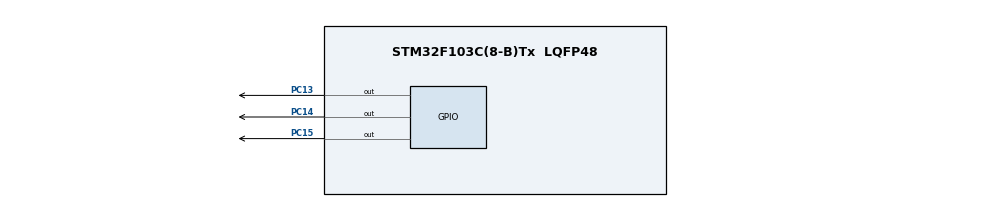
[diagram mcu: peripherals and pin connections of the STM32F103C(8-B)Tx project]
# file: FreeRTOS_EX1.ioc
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Mcu.Family=STM32F1
Mcu.Name=STM32F103C(8-B)Tx
Mcu.Package=LQFP48
NVIC.PriorityGroup=NVIC_PRIORITYGROUP_4
NVIC.TIM1_UP_IRQn=true\:15\:0\:true\:false\:true\:false\:true\:true
NVIC.TimeBase=TIM1_UP_IRQn
NVIC.TimeBaseIP=TIM1
PA13.Mode=Serial_Wire
PA13.Signal=SYS_JTMS-SWDIO
PA14.Mode=Serial_Wire
PA14.Signal=SYS_JTCK-SWCLK
PC13-TAMPER-RTC.Signal=GPIO_Output
PC14-OSC32_IN.Signal=GPIO_Output
PC15-OSC32_OUT.Signal=GPIO_Output
PD0-OSC_IN.Mode=HSE-External-Clock-Source
PD0-OSC_IN.Signal=RCC_OSC_IN
PD1-OSC_OUT.Mode=HSE-External-Clock-Source
PD1-OSC_OUT.Signal=RCC_OSC_OUT
ProjectManager.HeapSize=0x200
ProjectManager.StackSize=0x400
ProjectManager.TargetToolchain=STM32CubeIDE
RCC.APB1Freq_Value=8000000
RCC.APB2Freq_Value=8000000
VP_SYS_VS_tim1.Mode=TIM1
board=custom

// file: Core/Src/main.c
/* USER CODE BEGIN Header */
/**
  ******************************************************************************
  * @file           : main.c
  * @brief          : Main program body
  ******************************************************************************
  * @attention
  *
  * Copyright (c) 2024 STMicroelectronics.
  * All rights reserved.
  *
  * This software is licensed under terms that can be found in the LICENSE file
  * in the root directory of this software component.
  * If no LICENSE file comes with this software, it is provided AS-IS.
  *
  ******************************************************************************
  */
/* USER CODE END Header */
#include "main.h"

/* USER CODE BEGIN Includes */
#include "FreeRTOS.h"
#include "task.h"
#include <stdio.h>
/* USER CODE END Includes */

/* USER CODE BEGIN PD */
#define DWT_CTRL	*((volatile uint32_t *)0xE0001000)

/* USER CODE END PD */

void SystemClock_Config(void);
static void MX_GPIO_Init(void);
/* USER CODE BEGIN PFP */
void Task1Handler(void* Parameters);
void Task2Handler(void* Parameters);

/* USER CODE END PFP */

int main(void)
{

  /* MCU Configuration--------------------------------------------------------*/

  /* Reset of all peripherals, Initializes the Flash interface and the Systick. */
  HAL_Init();

  /* Configure the system clock */
  SystemClock_Config();

  /* Initialize all configured peripherals */
  MX_GPIO_Init();
  /* USER CODE BEGIN 2 */
  /*Enable Cycle Counter Feature of The Processor */
  DWT_CTRL |=  1;

  /*Configure Sysview target source files and start recording*/
  SEGGER_SYSVIEW_Conf();
  SEGGER_SYSVIEW_Start();

  TaskHandle_t Task1Handle,Task2Handle;
  BaseType_t Local_Status ;
  Local_Status = xTaskCreate(Task1Handler,"Task_1",200,"I'm Task1",2,&Task1Handle);

  configASSERT(Local_Status == pdPASS);
  Local_Status = xTaskCreate(Task2Handler,"Task_2",200,"I'm Task2",2,&Task2Handle);

  configASSERT(Local_Status == pdPASS);

  vTaskStartScheduler();
  /* USER CODE END 2 */

  /* Infinite loop */
  while (1)
  {

  }
}

void SystemClock_Config(void)
{
  RCC_OscInitTypeDef RCC_OscInitStruct = {0};
  RCC_ClkInitTypeDef RCC_ClkInitStruct = {0};

  /** Initializes the RCC Oscillators according to the specified parameters
  * in the RCC_OscInitTypeDef structure.
  */
  RCC_OscInitStruct.OscillatorType = RCC_OSCILLATORTYPE_HSI;
  RCC_OscInitStruct.HSIState = RCC_HSI_ON;
  RCC_OscInitStruct.HSICalibrationValue = RCC_HSICALIBRATION_DEFAULT;
  RCC_OscInitStruct.PLL.PLLState = RCC_PLL_NONE;
  if (HAL_RCC_OscConfig(&RCC_OscInitStruct) != HAL_OK)
  {
    Error_Handler();
  }

  /** Initializes the CPU, AHB and APB buses clocks
  */
  RCC_ClkInitStruct.ClockType = RCC_CLOCKTYPE_HCLK|RCC_CLOCKTYPE_SYSCLK
                              |RCC_CLOCKTYPE_PCLK1|RCC_CLOCKTYPE_PCLK2;
  RCC_ClkInitStruct.SYSCLKSource = RCC_SYSCLKSOURCE_HSI;
  RCC_ClkInitStruct.AHBCLKDivider = RCC_SYSCLK_DIV1;
  RCC_ClkInitStruct.APB1CLKDivider = RCC_HCLK_DIV1;
  RCC_ClkInitStruct.APB2CLKDivider = RCC_HCLK_DIV1;

  if (HAL_RCC_ClockConfig(&RCC_ClkInitStruct, FLASH_LATENCY_0) != HAL_OK)
  {
    Error_Handler();
  }
}

static void MX_GPIO_Init(void)
{
  GPIO_InitTypeDef GPIO_InitStruct = {0};

  /* GPIO Ports Clock Enable */
  __HAL_RCC_GPIOC_CLK_ENABLE();
  __HAL_RCC_GPIOD_CLK_ENABLE();
  __HAL_RCC_GPIOA_CLK_ENABLE();

  /*Configure GPIO pin Output Level */
  HAL_GPIO_WritePin(GPIOC, GPIO_PIN_13|GPIO_PIN_14|GPIO_PIN_15, GPIO_PIN_RESET);

  /*Configure GPIO pins : PC13 PC14 PC15 */
  GPIO_InitStruct.Pin = GPIO_PIN_13|GPIO_PIN_14|GPIO_PIN_15;
  GPIO_InitStruct.Mode = GPIO_MODE_OUTPUT_PP;
  GPIO_InitStruct.Pull = GPIO_NOPULL;
  GPIO_InitStruct.Speed = GPIO_SPEED_FREQ_LOW;
  HAL_GPIO_Init(GPIOC, &GPIO_InitStruct);

}

/* USER CODE BEGIN 4 */
void Task1Handler(void* Parameters)
{
	char Fstring[100];
	while(1)
	{
//		HAL_GPIO_TogglePin(GPIOC,GPIO_PIN_13);
		snprintf(Fstring,100,"%s\n",(char*)Parameters);
		SEGGER_SYSVIEW_PrintfTarget(Fstring);
//		for(int i=0;i<100000;i++)
			{

			}
		taskYIELD();
	}
}
void Task2Handler(void* Parameters)
{
	char Fstring[100];
	while(1)
	{
//		HAL_GPIO_TogglePin(GPIOC,GPIO_PIN_14);
		snprintf(Fstring,100,"%s\n",(char*)Parameters);
		SEGGER_SYSVIEW_PrintfTarget(Fstring);
//		for(int i=0;i<100000;i++)
			{

			}
		taskYIELD();
	}
}
/* USER CODE END 4 */

void HAL_TIM_PeriodElapsedCallback(TIM_HandleTypeDef *htim)
{
  if (htim->Instance == TIM1) {
    HAL_IncTick();
  }
}

void Error_Handler(void)
{
  __disable_irq();
  while (1)
  {
  }
}
